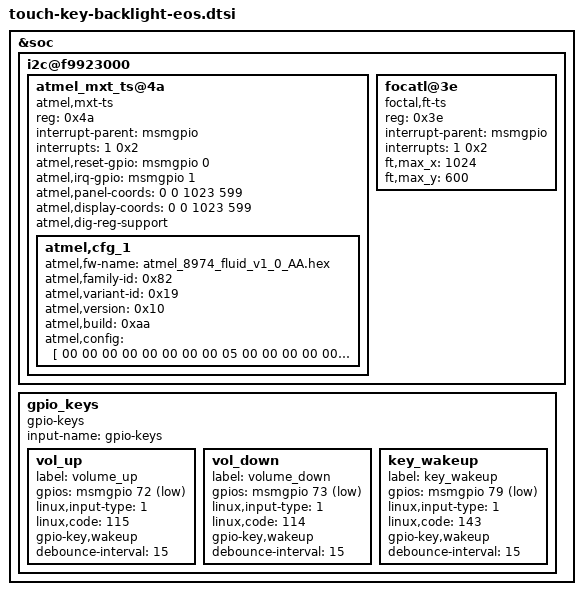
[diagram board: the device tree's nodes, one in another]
//for touchscreen and key and keypad-backlight

&soc {

	i2c@f9923000{
               atmel_mxt_ts@4a {
                       compatible = "atmel,mxt-ts";
                       reg = <0x4a>;
                       interrupt-parent = <&msmgpio>;
                       interrupts = <1 0x2>;
                       //vdd_ana-supply = <&pm8941_l18>;
                       //vcc_i2c-supply = <&pm8941_lvs1>;
                       atmel,reset-gpio = <&msmgpio 0 0x00>;
                       atmel,irq-gpio = <&msmgpio 1 0x00>;
                       atmel,panel-coords = <0  0 1023 599>;
                       atmel,display-coords = <0 0 1023 599>;
					   atmel,dig-reg-support;
                       //atmel,i2c-pull-up;
                       //atmel,no-force-update;
                       atmel,cfg_1 {
                               atmel,fw-name = "atmel_8974_fluid_v1_0_AA.hex";
                               atmel,family-id = <0x82>;
                               atmel,variant-id = <0x19>;
                               atmel,version = <0x10>;
                               atmel,build = <0xaa>;
                               atmel,config = [
                                       /* Object 6, Instance = 0 */
                                       00 00 00 00 00 00
                                       /* Object 38, Instance = 0 */
                                       00 00 05 00 00 00 00 00
                                       /* Object 7, Instance = 0 */
                                       ff ff ff 03
                                       /* Object 8, Instance = 0 */
                                       1c 00 0A 0A 00 00 05 2d 0a 19
                                       /* Object 9, Instance = 0 */
                                       8b 00 00 18 0E 00 50 32 02 04
                                       0a 05 05 00 0a 0a 0A 0A ff 03
                                       57 02 06 08 06 06 40 00 40 00
                                       12 0a 3c 3c 00 00
                                       /* Object 15, Instance = 0 */
                                       00 00 00 00 00 00 00 00 00 00
                                       00
                                       /* Object 18, Instance = 0 */
                                       00 00
                                       /* Object 19, Instance = 0 */
                                       00 00 00 0c 00 00
                                       /* Object 23, Instance = 0 */
                                       00 00 00 00 00 00 00 00 00 00
                                       00 00 00 00 00
                                       /* Object 25, Instance = 0 */
                                       00 00 00 00 00 00 00 00 00 00
                                       00 00 00 00 00
                                       /* Object 40, Instance = 0 */
                                       00 00 00 00 00
                                       /* Object 42, Instance = 0 */
                                       00 00 00 00 00 00 00 00 00 00
                                       /* Object 46, Instance = 0 */
                                       00 00 10 18 00 00 03 00 00 01
                                       /* Object 47, Instance = 0 */
                                       08 0A 28 0A 02 0A 00 8C 00 20
                                       00 00 00
                                       /* Object 55, Instance = 0 */
                                       00 00 00 00 00 00
                                       /* Object 56, Instance = 0 */
                                       01 00 00 38 05 09 09 09 09 09
                                       09 09 09 09 09 09 09 09 09 09
                                       09 09 09 09 09 09 09 05 03 00
                                       01 02 0c 04 00 00 00 00 00 00
                                       00 00
                                       /* Object 57, Instance = 0 */
                                       00 00 00
                                       /* Object 61, Instance = 0 */
                                       00 00 00 00 00
                                       /* Object 62, Instance = 0 */
                                       01 c2 e0 12 00 00 00 00 00 00
                                       03 09 11 17 05 00 0a 05 05 50
                                       19 19 34 0c 3f 00 00 00 00 00
                                       00 00 00 00 00 00 00 00 00 30
                                       00 00 00 01 00 00 00 00 00 00
                                       00 0f 23 00
                                       ];
                       };
               };
				focatl@3e{
                       compatible = "foctal,ft-ts";
                       reg = <0x3e>;
                       interrupt-parent = <&msmgpio>;
                       interrupts = <1 0x2>;
					   ft,max_x=<1024>;
					   ft,max_y=<600>;

				};
	};

	gpio_keys {
		compatible = "gpio-keys";
		input-name = "gpio-keys";

		vol_up {
			label = "volume_up";
			gpios = <&msmgpio 72 0x1>;
			linux,input-type = <1>;
			linux,code = <115>;
			gpio-key,wakeup;
			debounce-interval = <15>;
		};
		
		vol_down {
			label = "volume_down";
			gpios = <&msmgpio 73 0x1>;
			linux,input-type = <1>;
			linux,code = <114>;
			gpio-key,wakeup;
			debounce-interval = <15>;
		};	
		key_wakeup {
			label = "key_wakeup";
			gpios = <&msmgpio 79 0x1>;
			linux,input-type = <1>;
			linux,code = <143>;
			gpio-key,wakeup;
			debounce-interval = <15>;
		};			
	};
			

	
};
